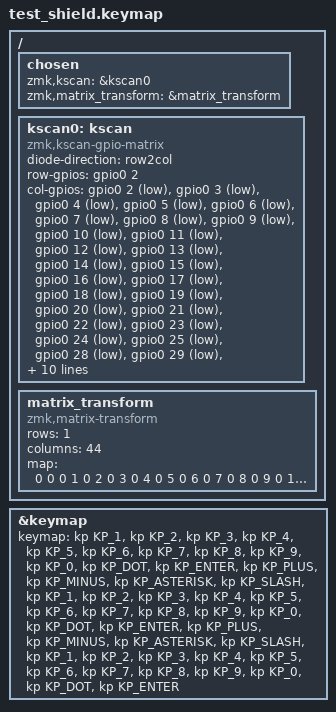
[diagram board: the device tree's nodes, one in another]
#include <zmk/app/boards/shields/keymap.h>

/ {
    chosen {
        zmk,kscan = &kscan0;
        zmk,matrix_transform = &matrix_transform;
    };

    kscan0: kscan {
        compatible = "zmk,kscan-gpio-matrix";
        diode-direction = "row2col";

        row-gpios = <&gpio0 2 GPIO_ACTIVE_HIGH>;

        // 移除 P0.00 P0.01 P0.26 P0.27
        col-gpios = <
            &gpio0 2  GPIO_ACTIVE_LOW
            &gpio0 3  GPIO_ACTIVE_LOW
            &gpio0 4  GPIO_ACTIVE_LOW
            &gpio0 5  GPIO_ACTIVE_LOW
            &gpio0 6  GPIO_ACTIVE_LOW
            &gpio0 7  GPIO_ACTIVE_LOW
            &gpio0 8  GPIO_ACTIVE_LOW
            &gpio0 9  GPIO_ACTIVE_LOW
            &gpio0 10 GPIO_ACTIVE_LOW
            &gpio0 11 GPIO_ACTIVE_LOW
            &gpio0 12 GPIO_ACTIVE_LOW
            &gpio0 13 GPIO_ACTIVE_LOW
            &gpio0 14 GPIO_ACTIVE_LOW
            &gpio0 15 GPIO_ACTIVE_LOW
            &gpio0 16 GPIO_ACTIVE_LOW
            &gpio0 17 GPIO_ACTIVE_LOW
            &gpio0 18 GPIO_ACTIVE_LOW
            &gpio0 19 GPIO_ACTIVE_LOW
            &gpio0 20 GPIO_ACTIVE_LOW
            &gpio0 21 GPIO_ACTIVE_LOW
            &gpio0 22 GPIO_ACTIVE_LOW
            &gpio0 23 GPIO_ACTIVE_LOW
            &gpio0 24 GPIO_ACTIVE_LOW
            &gpio0 25 GPIO_ACTIVE_LOW
            &gpio0 28 GPIO_ACTIVE_LOW
            &gpio0 29 GPIO_ACTIVE_LOW
            &gpio0 30 GPIO_ACTIVE_LOW
            &gpio0 31 GPIO_ACTIVE_LOW
            &gpio1 0  GPIO_ACTIVE_LOW
            &gpio1 1  GPIO_ACTIVE_LOW
            &gpio1 2  GPIO_ACTIVE_LOW
            &gpio1 3  GPIO_ACTIVE_LOW
            &gpio1 4  GPIO_ACTIVE_LOW
            &gpio1 5  GPIO_ACTIVE_LOW
            &gpio1 6  GPIO_ACTIVE_LOW
            &gpio1 7  GPIO_ACTIVE_LOW
            &gpio1 8  GPIO_ACTIVE_LOW
            &gpio1 9  GPIO_ACTIVE_LOW
            &gpio1 10 GPIO_ACTIVE_LOW
            &gpio1 11 GPIO_ACTIVE_LOW
            &gpio1 12 GPIO_ACTIVE_LOW
            &gpio1 13 GPIO_ACTIVE_LOW
            &gpio1 14 GPIO_ACTIVE_LOW
            &gpio1 15 GPIO_ACTIVE_LOW
        >;

        debounce-press-ms = <5>;
        debounce-release-ms = <5>;
    };

    matrix_transform: matrix_transform {
        compatible = "zmk,matrix-transform";
        rows = <1>;
        columns = <44>;
        map = <
            0 0  0 1  0 2  0 3
            0 4  0 5  0 6  0 7
            0 8  0 9  0 10 0 11
            0 12 0 13 0 14 0 15
            0 16 0 17 0 18 0 19
            0 20 0 21 0 22 0 23
            0 24 0 25 0 26 0 27
            0 28 0 29 0 30 0 31
            0 32 0 33 0 34 0 35
            0 36 0 37 0 38 0 39
            0 40 0 41 0 42 0 43
        >;
    };
};

&keymap {
    keymap = <
        &kp KP_1  &kp KP_2  &kp KP_3  &kp KP_4
        &kp KP_5  &kp KP_6  &kp KP_7  &kp KP_8
        &kp KP_9  &kp KP_0  &kp KP_DOT &kp KP_ENTER
        &kp KP_PLUS &kp KP_MINUS &kp KP_ASTERISK &kp KP_SLASH
        &kp KP_1  &kp KP_2  &kp KP_3  &kp KP_4
        &kp KP_5  &kp KP_6  &kp KP_7  &kp KP_8
        &kp KP_9  &kp KP_0  &kp KP_DOT &kp KP_ENTER
        &kp KP_PLUS &kp KP_MINUS &kp KP_ASTERISK &kp KP_SLASH
        &kp KP_1  &kp KP_2  &kp KP_3  &kp KP_4
        &kp KP_5  &kp KP_6  &kp KP_7  &kp KP_8
        &kp KP_9  &kp KP_0  &kp KP_DOT &kp KP_ENTER
    >;
};
